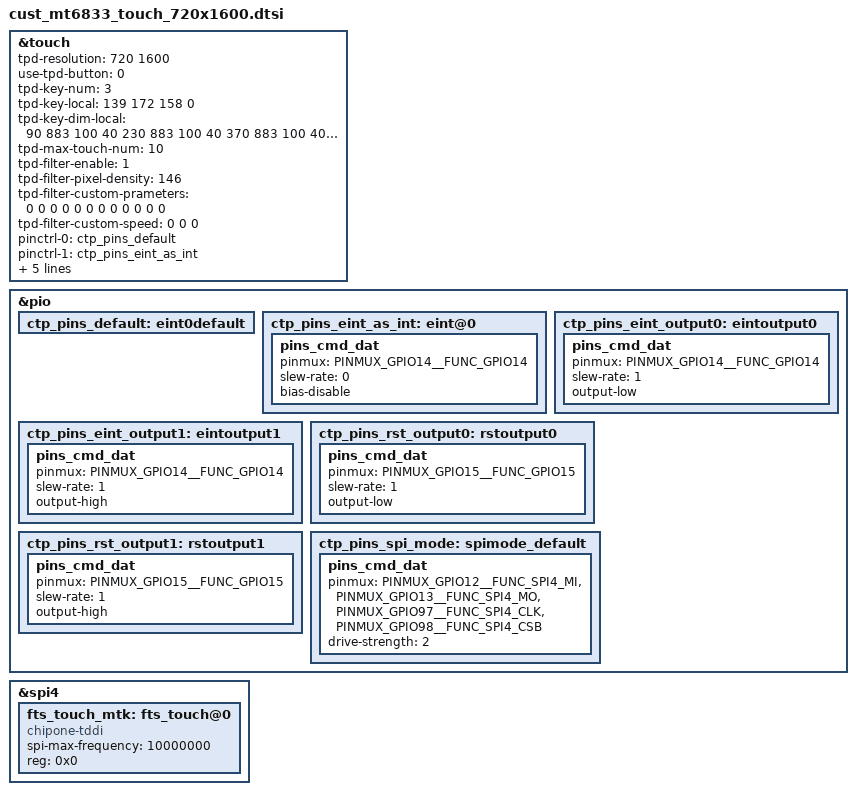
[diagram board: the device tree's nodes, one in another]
/*
 * Copyright (c) 2019 MediaTek Inc.
 *
 * This program is free software; you can redistribute it and/or modify
 * it under the terms of the GNU General Public License version 2 as
 * published by the Free Software Foundation.
 *
 * This program is distributed in the hope that it will be useful,
 * but WITHOUT ANY WARRANTY; without even the implied warranty of
 * MERCHANTABILITY or FITNESS FOR A PARTICULAR PURPOSE.  See the
 * GNU General Public License for more details.
 */
/* TOUCH start */
&touch {
	tpd-resolution = <720 1600>;
	use-tpd-button = <0>;
	tpd-key-num = <3>;
	tpd-key-local= <139 172 158 0>;
	tpd-key-dim-local = <90 883 100 40 230
				 883 100 40 370 883 100 40 0 0 0 0>;
	tpd-max-touch-num = <10>;
	tpd-filter-enable = <1>;
	tpd-filter-pixel-density = <146>;
	tpd-filter-custom-prameters = <0 0 0 0 0 0 0 0 0 0 0 0>;
	tpd-filter-custom-speed = <0 0 0>;
	pinctrl-names = "default", "state_eint_as_int", "state_eint_output0",
		"state_eint_output1", "state_rst_output0", "state_rst_output1", "state_spi_mode";
	pinctrl-0 = <&ctp_pins_default>;
	pinctrl-1 = <&ctp_pins_eint_as_int>;
	pinctrl-2 = <&ctp_pins_eint_output0>;
	pinctrl-3 = <&ctp_pins_eint_output1>;
	pinctrl-4 = <&ctp_pins_rst_output0>;
	pinctrl-5 = <&ctp_pins_rst_output1>;
    pinctrl-6 = <&ctp_pins_spi_mode>;
	status = "okay";
};

&pio {
	ctp_pins_default: eint0default {
	};
	ctp_pins_eint_as_int: eint@0 {
		pins_cmd_dat {
			pinmux = <PINMUX_GPIO14__FUNC_GPIO14>;
			slew-rate = <0>;
			bias-disable;
		};
	};
	ctp_pins_eint_output0: eintoutput0 {
		pins_cmd_dat {
			pinmux = <PINMUX_GPIO14__FUNC_GPIO14>;
			slew-rate = <1>;
			output-low;
		};
	};
	ctp_pins_eint_output1: eintoutput1 {
		pins_cmd_dat {
			pinmux = <PINMUX_GPIO14__FUNC_GPIO14>;
			slew-rate = <1>;
			output-high;
		};
	};
	ctp_pins_rst_output0: rstoutput0 {
		pins_cmd_dat {
			pinmux = <PINMUX_GPIO15__FUNC_GPIO15>;
			slew-rate = <1>;
			output-low;
		};
	};
	ctp_pins_rst_output1: rstoutput1 {
		pins_cmd_dat {
			pinmux = <PINMUX_GPIO15__FUNC_GPIO15>;
			slew-rate = <1>;
			output-high;
		};
	};
    	ctp_pins_spi_mode: spimode_default {
		pins_cmd_dat {
			pinmux = <PINMUX_GPIO12__FUNC_SPI4_MI>,
				<PINMUX_GPIO13__FUNC_SPI4_MO>,
				<PINMUX_GPIO97__FUNC_SPI4_CLK>,
				<PINMUX_GPIO98__FUNC_SPI4_CSB>;
			drive-strength = <2>;
		};
	};
};

&spi4 {
   #address-cells = <1>;
   #size-cells = <0>;
	fts_touch_mtk:fts_touch@0{
		compatible = "chipone-tddi";
                spi-max-frequency = <10000000>;
                reg = <0x0>;
                status = "okay";
        };
};
/* TOUCH end */
